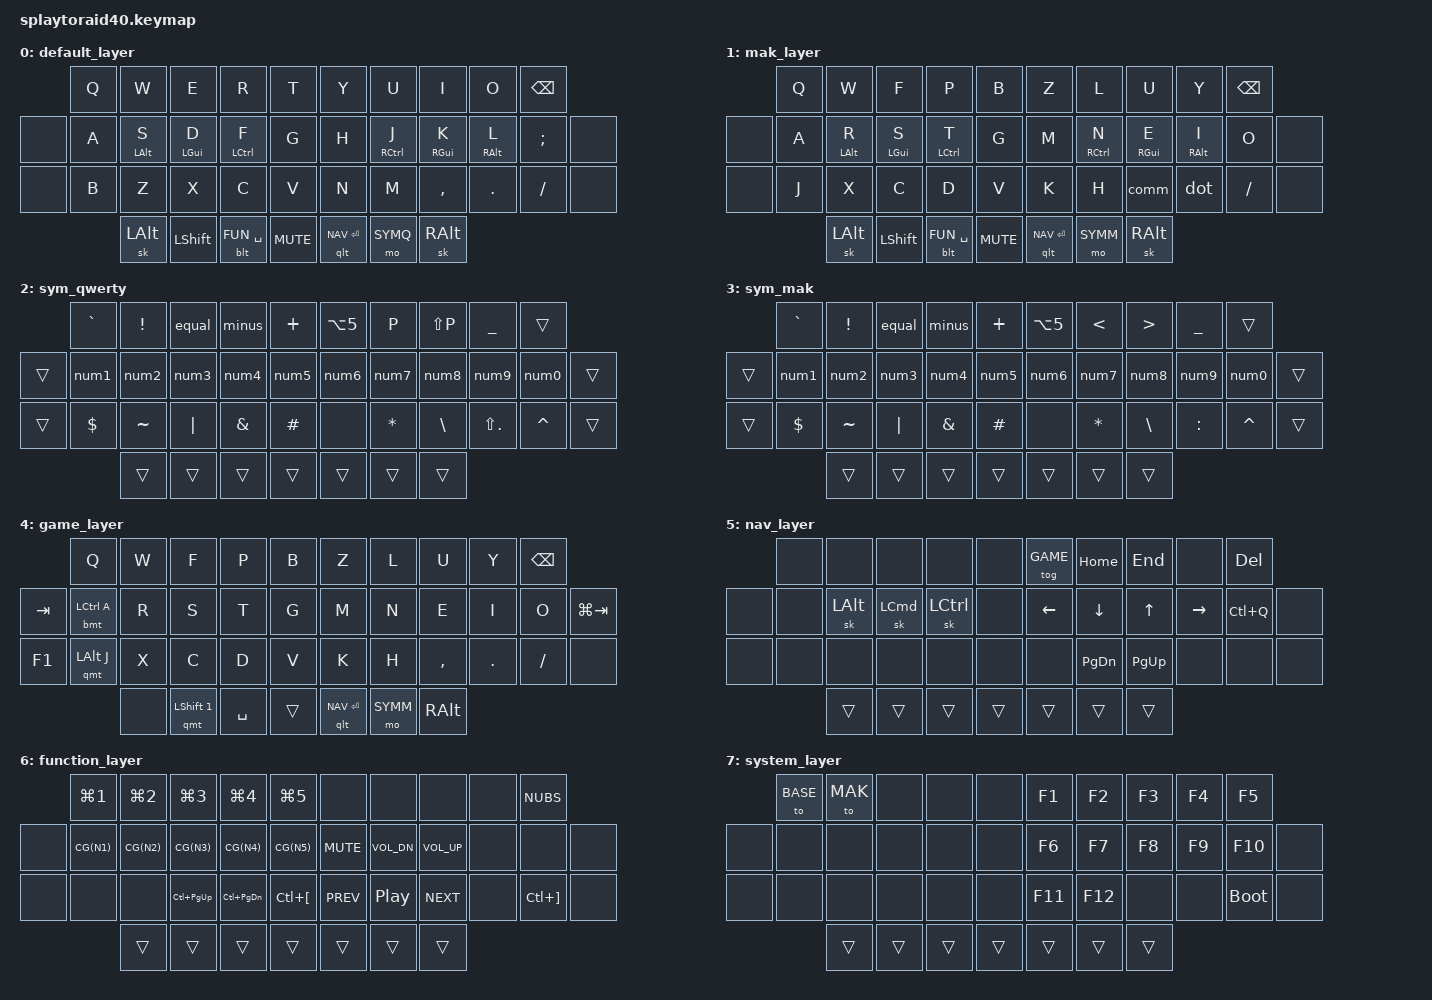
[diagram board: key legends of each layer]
#include <behaviors.dtsi>
#include <dt-bindings/zmk/keys.h>
#include <dt-bindings/zmk/rgb.h>
#include <dt-bindings/zmk/bt.h>
#include <dt-bindings/zmk/outputs.h>

/ {
    #define SPLAYTORAID
    #include "smol.dtsi"
    
    keymap {
        compatible = "zmk,keymap";

        default_layer {
            bindings = <
                            &kp Q      &kp W       &kp E       &kp R          &kp T          &kp Y          &kp U          &kp I       &kp O       &kp BSPC
                &none       &kp A      &hml LALT S &hml LGUI D &hml LCTRL F   &kp G          &kp H          &hmr RCTRL J   &hmr RGUI K &hmr RALT L &kp SEMI &none      
                &none       &kp B      &kp Z       &kp X       &kp C          &kp V          &kp N          &kp M          &kp COMMA   &kp DOT     &kp FSLH &none     
                                       &sk LALT    &kp  LSHFT      &blt FUN SPACE  &kp C_MUTE   &qlt NAV RET   &mo SYMQ    &sk RALT  
            >;
            sensor-bindings = <&inc_dec_kp C_VOL_DN C_VOL_UP>;
        };
        mak_layer {
            bindings = <
                            &kp Q      &kp W       &kp F       &kp P          &kp B          &kp Z          &kp L          &kp U       &kp Y       &kp BSPC
                &none       &kp A      &hml LALT R &hml LGUI S &hml LCTRL T   &kp G          &kp M          &hmr RCTRL N   &hmr RGUI E &hmr RALT I &kp O    &none      
                &none       &kp J      &kp X       &kp C       &kp D          &kp V          &kp K          &kp H          &comm       &dot        &kp FSLH &none     
                                       &sk LALT    &kp  LSHFT      &blt FUN SPACE  &kp C_MUTE   &qlt NAV RET   &mo SYMM    &sk RALT  
            >;
            sensor-bindings = <&inc_dec_kp C_VOL_DN C_VOL_UP>;
        };
        sym_qwerty {
            bindings = <
                            &kp GRAVE  &kp EXCL   &equal      &minus          &kp PLUS      &kp LA(N5)      &kp P          &kp LS(P)   &kp UNDER  &trans   
                &trans      &num1      &num2      &num3       &num4           &num5         &num6           &num7          &num8       &num9      &num0      &trans  
                &trans      &kp DLLR   &kp TILDE  &kp PIPE    &kp AMPS        &kp HASH      &none           &kp STAR       &kp BSLH    &kp LS(DOT)&kp CARET  &trans  
                                          &trans  &trans      &trans  &trans  &trans        &trans          &trans
            >;
        };
        sym_mak {
            bindings = <
                            &kp GRAVE  &kp EXCL   &equal      &minus          &kp PLUS      &kp LA(N5)      &kp LT         &kp GT      &kp UNDER  &trans   
                &trans      &num1      &num2      &num3       &num4           &num5         &num6           &num7          &num8       &num9      &num0     &trans  
                &trans      &kp DLLR   &kp TILDE  &kp PIPE    &kp AMPS        &kp HASH      &none           &kp STAR       &kp BSLH    &kp COLON  &kp CARET &trans  
                                          &trans  &trans      &trans  &trans  &trans        &trans          &trans
            >;
        };
        game_layer {
            bindings = <
                           &kp Q      &kp W       &kp F       &kp P          &kp B          &kp Z          &kp L          &kp U       &kp Y       &kp BSPC
             &kp TAB       &bmt LCTRL A&kp R      &kp S       &kp T          &kp G          &kp M          &kp N          &kp E       &kp I       &kp O      &kp LG(TAB)
             &kp F1        &qmt LALT J&kp X       &kp C       &kp D          &kp V          &kp K          &kp H          &kp COMMA   &kp DOT     &kp SLASH  &none
                                                  &none       &qmt LSHFT N1  &kp SPACE&trans&qlt NAV RET   &mo SYMM       &kp RALT    
            >;
        };
        nav_layer {
            bindings = <
                            &none       &none       &none      &none          &none         &tog GAME       &kp HOME       &kp END      &none      &kp DEL
                &none       &none       &sk LALT    &sk LCMD   &sk LCTRL      &none         &kp LEFT        &kp DOWN       &kp UP       &kp RIGHT  &kp LC(Q)&none
                &none       &none       &none       &none      &none          &none         &none           &kp PG_DN      &kp PG_UP    &none      &none    &none
                                                   &trans  &trans    &trans   &trans   &trans     &trans          &trans
            >;
        };
        function_layer {
            bindings = <
                            &kp LG(N1)    &kp LG(N2)   &kp LG(N3)   &kp LG(N4)    &kp LG(N5)    &none      &none         &none        &none        &kp NUBS
                &none       &kp CG(N1)    &kp CG(N2)   &kp CG(N3)   &kp CG(N4)    &kp CG(N5)    &kp C_MUTE &kp C_VOL_DN  &kp C_VOL_UP &none        &none       &none
                &none       &none         &none        &kp LC(PG_UP)&kp LC(PG_DN) &kp LC(LBKT)  &kp C_PREV &kp C_PP      &kp C_NEXT   &none        &kp LC(RBKT)&none
                                                &trans     &trans   &trans  &trans      &trans        &trans    &trans
            >;
        };
        system_layer {
            bindings = <
                            &to BASE     &to MAK        &none        &none          &none         &kp F1    &kp F2        &kp F3       &kp F4       &kp F5        
                &none       &none        &none          &none        &none          &none         &kp F6    &kp F7        &kp F8       &kp F9       &kp F10     &none
                &none       &none        &none          &none        &none          &none         &kp F11   &kp F12       &none        &none        &bootloader &none
                                                &trans  &trans   &trans    &trans         &trans        &trans          &trans
            >;
        };
    };
};
